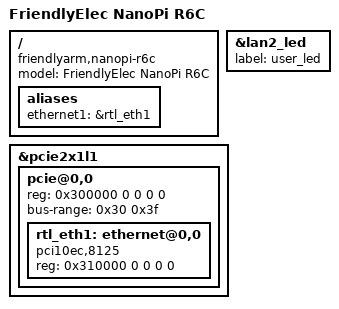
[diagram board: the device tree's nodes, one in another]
// SPDX-License-Identifier: (GPL-2.0+ OR MIT)

/dts-v1/;

#include "rk3588s-nanopi-r6.dtsi"

/ {
	model = "FriendlyElec NanoPi R6C";
	compatible = "friendlyarm,nanopi-r6c", "rockchip,rk3588s";

	aliases {
		ethernet1 = &rtl_eth1;
	};
};

&lan2_led {
	label = "user_led";
};

&pcie2x1l1 {
	/* on-board RTL8125 2.5GbE NIC */
	pcie@0,0 {
		reg = <0x300000 0 0 0 0>;
		#address-cells = <3>;
		#size-cells = <2>;
		ranges;
		device_type = "pci";
		bus-range = <0x30 0x3f>;

		rtl_eth1: ethernet@0,0 {
			compatible = "pci10ec,8125";
			reg = <0x310000 0 0 0 0>;
		};
	};
};
